# STM32F427AGH6 register map
File version: 1.0
STM32F427AGH6,STM32F427AIH6,STM32F427IGH6,STM32F427IGT6,STM32F427IIH6,STM32F427IIH7,STM32F427IIT6,STM32F427IIT7,STM32F427VGT6,STM32F427VIT6,STM32F427VIT7,STM32F427ZGT6,STM32F427ZIT6,STM32F427ZIT7,STM32F429AGH6,STM32F429AIH6,STM32F429BET6,STM32F429BGT6,STM32F429BIT6,STM32F429BIT7,STM32F429IEH6,STM32F429IET6,STM32F429IGH6,STM32F429IGT6,STM32F429IIH6,STM32F429IIT6,STM32F429NEH6,STM32F429NGH6,STM32F429NIH6,STM32F429NIH7,STM32F429VET6,STM32F429VGT6,STM32F429VIT6,STM32F429ZET6,STM32F429ZGT6,STM32F429ZGY6,STM32F429ZIT6,STM32F429ZIT7,STM32F429ZIY6,STM32F429ZIY7
Registers are 32-bit, access not given, reset 0x0 unless marked. A register's access mark holds for its fields unless they carry their own. Offsets are from the block's base; lines under a group give offsets from that group; [hi:lo] are bit positions; {n}, {i} and the like mark numbered series; 'fields as' and 'values as' point back to an identical list; <NAME> marks a mode.

## Memory map
0x40000000 TIM2
0x40000400 TIM3
0x40000800 TIM4
0x40000C00 TIM5
0x40001000 TIM6
0x40001400 TIM7
0x40001800 TIM12
0x40001C00 TIM13
0x40002000 TIM14
0x40002800 RTC
0x40002800 BKP
0x40002C00 WWDG
0x40003000 IWDG
0x40003800 SPI2
0x40003C00 SPI3
0x40004400 USART2
0x40004800 USART3
0x40004C00 UART4
0x40005000 UART5
0x40005400 I2C1
0x40005800 I2C2
0x40005C00 I2C3
0x40006400 CAN1
0x40006800 CAN2
0x40007000 PWR
0x40007400 DAC
0x40007800 UART7
0x40007C00 UART8
0x40010000 TIM1
0x40010400 TIM8
0x40011000 USART1
0x40011400 USART6
0x40012000 ADC1
0x40012100 ADC2
0x40012300 ADC3
0x40012C00 SDIO
0x40013000 SPI1
0x40013400 SPI4
0x40013800 SYSCFG
0x40013C00 EXTI
0x40014000 TIM9
0x40014400 TIM10
0x40014800 TIM11
0x40015000 SPI5
0x40015400 SPI6
0x40015800 SAI1
0x40016800 LTDC
0x40020000 GPIOA
0x40020400 GPIOB
0x40020800 GPIOC
0x40020C00 GPIOD
0x40021000 GPIOE
0x40021400 GPIOF
0x40021800 GPIOG
0x40021C00 GPIOH
0x40022000 GPIOI
0x40022400 GPIOJ
0x40022800 GPIOK
0x40023000 CRC
0x40023800 RCC
0x40023C00 FLASH
0x40026000 DMA1
0x40026400 DMA2
0x40028000 ETH
0x4002B000 DMA2D
0x40040000 USB_OTG_HS
0x50000000 USB_OTG_FS
0x50050000 DCMI
0x50060800 RNG
0xA0000000 FMC
0xA0000000 FSMC

## TIM2
Base 0x40000000
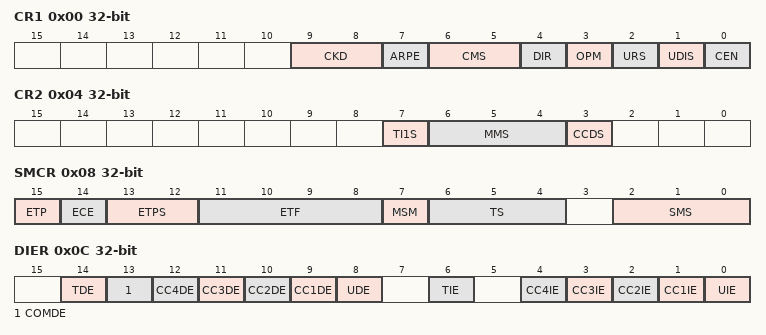
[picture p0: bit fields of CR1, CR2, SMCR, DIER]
0x00 CR1
  [9:8] CKD, [7] ARPE, [6:5] CMS, [4] DIR, [3] OPM, [2] URS, [1] UDIS, [0] CEN
0x04 CR2
  [7] TI1S, [6:4] MMS, [3] CCDS
0x08 SMCR
  [15] ETP, [14] ECE, [13:12] ETPS, [11:8] ETF, [7] MSM, [6:4] TS, [2:0] SMS
0x0C DIER
  [14] TDE, [13] COMDE, [n+8] CC{n}DE (n=1..4), [8] UDE, [6] TIE, [n] CC{n}IE (n=1..4), [0] UIE
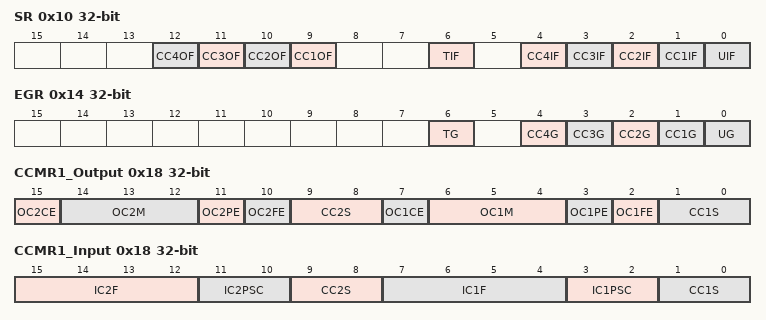
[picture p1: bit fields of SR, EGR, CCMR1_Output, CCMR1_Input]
0x10 SR
  [n+8] CC{n}OF (n=1..4), [6] TIF, [n] CC{n}IF (n=1..4), [0] UIF
0x14 EGR
  [6] TG, [n] CC{n}G (n=1..4), [0] UG
0x18 CCMR1_Output
  [15] OC2CE, [14:12] OC2M, [11] OC2PE, [10] OC2FE, [9:8] CC2S, [7] OC1CE, [6:4] OC1M, [3] OC1PE, [2] OC1FE, [1:0] CC1S
0x18 CCMR1_Input
  [15:12] IC2F, [11:10] IC2PSC, [9:8] CC2S, [7:4] IC1F, [3:2] IC1PSC, [1:0] CC1S
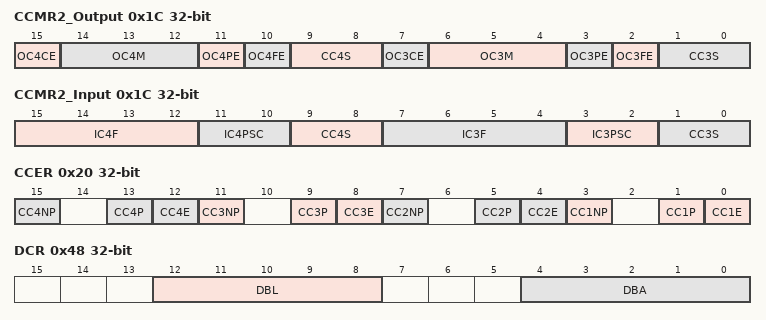
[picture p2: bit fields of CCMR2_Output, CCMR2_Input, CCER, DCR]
0x1C CCMR2_Output
  [15] OC4CE, [14:12] OC4M, [11] OC4PE, [10] OC4FE, [9:8] CC4S, [7] OC3CE, [6:4] OC3M, [3] OC3PE, [2] OC3FE, [1:0] CC3S
0x1C CCMR2_Input
  [15:12] IC4F, [11:10] IC4PSC, [9:8] CC4S, [7:4] IC3F, [3:2] IC3PSC, [1:0] CC3S
0x20 CCER
  [4n-1] CC{n}NP (n=1..4), [4n-3] CC{n}P (n=1..4), [4n-4] CC{n}E (n=1..4)
0x24 CNT
0x28 PSC
  [15:0] PSC
0x2C ARR
{0x30+4i} CCR{i} (i=1..4)
0x48 DCR
  [12:8] DBL, [4:0] DBA
0x4C DMAR
  [15:0] DMAB
0x50 OR
  [11:10] ITR1_RMP

## TIM3
Base 0x40000400
Registers as TIM2, without OR.

## TIM4
Base 0x40000800
Registers as TIM2, without OR.

## TIM5
Base 0x40000C00
Registers as TIM2; these are added or differ:
0x50 OR
  [7:6] IT4_RMP

## TIM6
Base 0x40001000
Same registers: TIM7 0x40001400
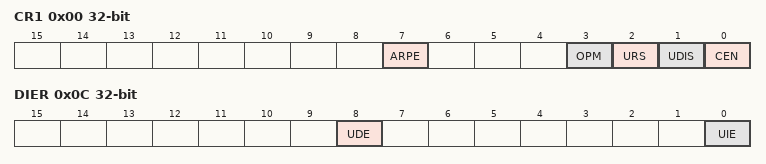
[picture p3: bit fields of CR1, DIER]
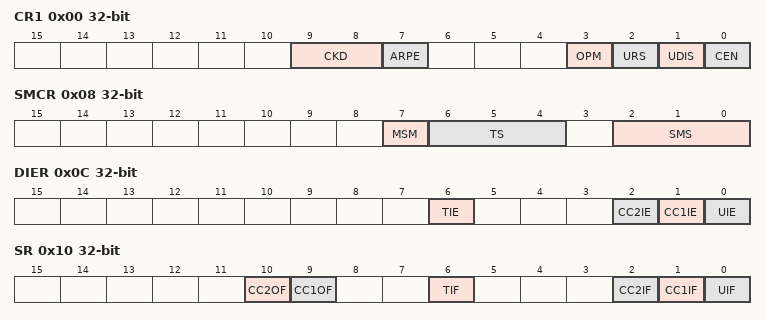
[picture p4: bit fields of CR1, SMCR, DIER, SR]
0x00 CR1
  [7] ARPE, [3] OPM, [2] URS, [1] UDIS, [0] CEN
0x04 CR2
  [6:4] MMS
0x0C DIER
  [8] UDE, [0] UIE
0x10 SR
  [0] UIF
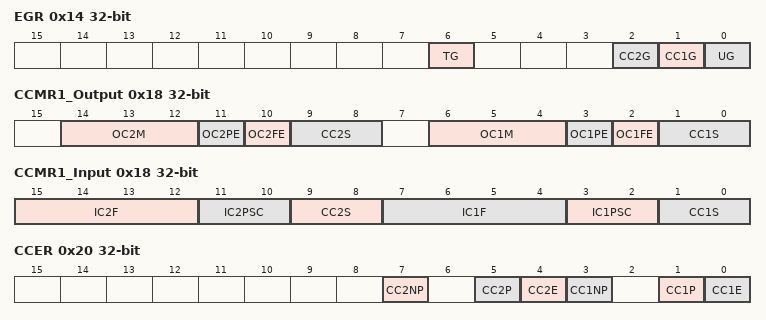
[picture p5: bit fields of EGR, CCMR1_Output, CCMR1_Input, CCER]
0x14 EGR
  [0] UG
0x24 CNT
  [15:0] CNT
0x28 PSC
  [15:0] PSC
0x2C ARR
  [15:0] ARR

## TIM12
Base 0x40001800
Same registers: TIM9 0x40014000
0x00 CR1
  [9:8] CKD, [7] ARPE, [3] OPM, [2] URS, [1] UDIS, [0] CEN
0x08 SMCR
  [7] MSM, [6:4] TS, [2:0] SMS
0x0C DIER
  [6] TIE, [2] CC2IE, [1] CC1IE, [0] UIE
0x10 SR
  [10] CC2OF, [9] CC1OF, [6] TIF, [2] CC2IF, [1] CC1IF, [0] UIF
0x14 EGR
  [6] TG, [2] CC2G, [1] CC1G, [0] UG
0x18 CCMR1_Output
  [14:12] OC2M, [11] OC2PE, [10] OC2FE, [9:8] CC2S, [6:4] OC1M, [3] OC1PE, [2] OC1FE, [1:0] CC1S
0x18 CCMR1_Input
  [15:12] IC2F, [11:10] IC2PSC, [9:8] CC2S, [7:4] IC1F, [3:2] IC1PSC, [1:0] CC1S
0x20 CCER
  [7] CC2NP, [5] CC2P, [4] CC2E, [3] CC1NP, [1] CC1P, [0] CC1E
0x24 CNT
  [15:0] CNT
0x28 PSC
  [15:0] PSC
0x2C ARR
  [15:0] ARR
0x34 CCR1
  [15:0] CCR1
0x38 CCR2
  [15:0] CCR2
